# nrf7120E_enga_application register map
Vendor: Nordic Semiconductor; Series: nrf71; File version: 1
CPU: CM33 r0p4, little endian, MPU, FPU, 3 interrupt priority bits, 270 interrupts, 4 SAU regions
Registers are 32-bit, read-write, reset 0x0 unless marked. A register's access mark holds for its fields unless they carry their own. Offsets are from the block's base; [hi:lo] are bit positions; lines under a group give offsets from that group; 'fields as' and 'values as' point back to an identical list.

## GLOBAL_LFRC_NS — LFRC peripheral 0
Base 0x40123000
Same registers: GLOBAL_LFRC_S 0x50123000
0x00 TASKS_CAL wo — Start the calibration of RC oscillator
  [0] TASKS_CAL
    1=Trigger task
0x04 TASKS_CANCELCAL wo — Cancel the calibration
  [0] TASKS_CANCELCAL
    1=Trigger task
0x100 EVENTS_CALDONE — Calibration done
  [0] EVENTS_CALDONE
    0=NotGenerated (Event not generated); 1=Generated (Event generated)
0x104 EVENTS_TRIMDONE — Trim done
  [0] EVENTS_TRIMDONE
    values as EVENTS_CALDONE.EVENTS_CALDONE
0x108 EVENTS_TRIMERROR — Trim error
  [0] EVENTS_TRIMERROR
    values as EVENTS_CALDONE.EVENTS_CALDONE
0x10C EVENTS_CKSYNSTARTED — Synth clock started
  [0] EVENTS_CKSYNSTARTED
    values as EVENTS_CALDONE.EVENTS_CALDONE
0x110 EVENTS_CKLFRCSTARTED — LFRC clock started
  [0] EVENTS_CKLFRCSTARTED
    values as EVENTS_CALDONE.EVENTS_CALDONE
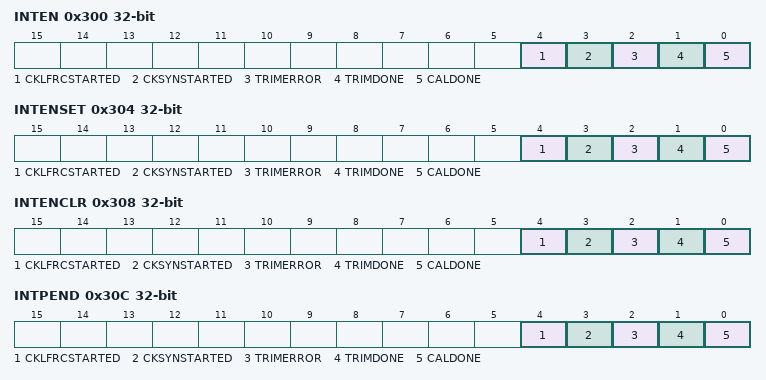
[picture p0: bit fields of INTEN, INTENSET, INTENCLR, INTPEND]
0x300 INTEN — Enable or disable interrupt
  [all] fields
    0=Disabled; 1=Enabled
  [4] CKLFRCSTARTED — Enable or disable interrupt for event CKLFRCSTARTED
  [3] CKSYNSTARTED — Enable or disable interrupt for event CKSYNSTARTED
  [2] TRIMERROR — Enable or disable interrupt for event TRIMERROR
  [1] TRIMDONE — Enable or disable interrupt for event TRIMDONE
  [0] CALDONE — Enable or disable interrupt for event CALDONE
0x304 INTENSET — Enable interrupt
  [all] fields
    on read: 0=Disabled (Read: Disabled); 1=Enabled (Read: Enabled) | on write: 1=Set (Enable)
  [4] CKLFRCSTARTED write-1-sets — Write '1' to enable interrupt for event CKLFRCSTARTED
  [3] CKSYNSTARTED write-1-sets — Write '1' to enable interrupt for event CKSYNSTARTED
  [2] TRIMERROR write-1-sets — Write '1' to enable interrupt for event TRIMERROR
  [1] TRIMDONE write-1-sets — Write '1' to enable interrupt for event TRIMDONE
  [0] CALDONE write-1-sets — Write '1' to enable interrupt for event CALDONE
0x308 INTENCLR — Disable interrupt
  [all] fields
    on read: 0=Disabled (Read: Disabled); 1=Enabled (Read: Enabled) | on write: 1=Clear (Disable)
  [4] CKLFRCSTARTED write-1-clears — Write '1' to disable interrupt for event CKLFRCSTARTED
  [3] CKSYNSTARTED write-1-clears — Write '1' to disable interrupt for event CKSYNSTARTED
  [2] TRIMERROR write-1-clears — Write '1' to disable interrupt for event TRIMERROR
  [1] TRIMDONE write-1-clears — Write '1' to disable interrupt for event TRIMDONE
  [0] CALDONE write-1-clears — Write '1' to disable interrupt for event CALDONE
0x30C INTPEND ro — Pending interrupts
  [all] fields
    on read: 0=NotPending (Read: Not pending); 1=Pending (Read: Pending)
  [4] CKLFRCSTARTED — Read pending status of interrupt for event CKLFRCSTARTED
  [3] CKSYNSTARTED — Read pending status of interrupt for event CKSYNSTARTED
  [2] TRIMERROR — Read pending status of interrupt for event TRIMERROR
  [1] TRIMDONE — Read pending status of interrupt for event TRIMDONE
  [0] CALDONE — Read pending status of interrupt for event CALDONE
0x400 STATUSTRIM ro reset 0xA — Current LFRCOSC trimming value.
  [5:0] VAL — TRIM value
0x420 CAL group — Unspecified
  0x00 LENGTH reset 0x2 — Measurement cycle count length used while calibration
    [2:0] LENGTH — Number of cycles
      0=N64 (64 cycles); 1=N128 (128 cycles); 2=N256 (256 cycles); 3=N512 (512 cycles)
  0x04 TRIMLIMITLO — Lower trim limit
    [17:0] VALUE — TRIM limit value.
  0x08 TRIMLIMITHI reset 0x3FFFF — Higher trim limit
    [17:0] VALUE — TRIM limit value
  0x18 LFRCOSCTRIM reset 0x2C — Initial coarse frequency trimming value for the oscillator.
    [5:0] VAL — TRIM value
0x480 MIRROR reset 0x1 — Enable LOCK for mirrored registers
  [0] LOCK — Lock for mirrored registers
    0=Disabled (Lock disabled); 1=Enabled (Lock enabled)
